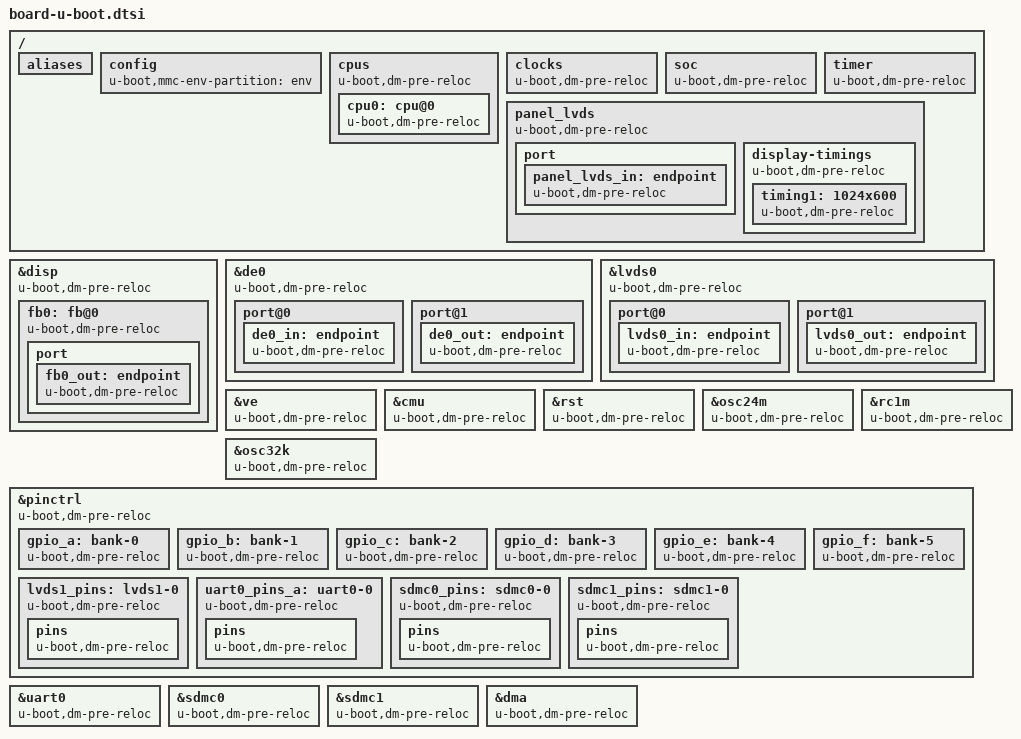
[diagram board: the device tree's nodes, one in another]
/ {
	aliases {
	};

	config {
		u-boot,mmc-env-partition = "env";
	};

	cpus {
		u-boot,dm-pre-reloc;
		cpu0: cpu@0 {
			u-boot,dm-pre-reloc;
		};
	};

	clocks {
		u-boot,dm-pre-reloc;
	};

	soc {
		u-boot,dm-pre-reloc;
	};

	timer {
		u-boot,dm-pre-reloc;
	};

	panel_lvds {
		u-boot,dm-pre-reloc;
		port {
			panel_lvds_in: endpoint {
				u-boot,dm-pre-reloc;
			};
		};

		display-timings {
			u-boot,dm-pre-reloc;
			timing1: 1024x600 {
				u-boot,dm-pre-reloc;
			};
		};
	};
};

&disp {
	u-boot,dm-pre-reloc;
	fb0: fb@0 {
	     u-boot,dm-pre-reloc;
		port {
			fb0_out: endpoint {
				u-boot,dm-pre-reloc;
			};
		};
	};
};
&de0 {
	u-boot,dm-pre-reloc;
	port@0 {
		de0_in: endpoint {
			u-boot,dm-pre-reloc;
		};
	};

	port@1 {
		de0_out: endpoint {
			u-boot,dm-pre-reloc;
		};
	};
};
&lvds0 {
	u-boot,dm-pre-reloc;
	port@0 {
		lvds0_in: endpoint {
			u-boot,dm-pre-reloc;
		};
	};

	port@1 {
		lvds0_out: endpoint {
			u-boot,dm-pre-reloc;
		};
	};
};
&ve {
	u-boot,dm-pre-reloc;
};

&cmu {
	u-boot,dm-pre-reloc;
};

&rst {
	u-boot,dm-pre-reloc;
};

&osc24m {
	u-boot,dm-pre-reloc;
};

&rc1m {
	u-boot,dm-pre-reloc;
};

&osc32k {
	u-boot,dm-pre-reloc;
};

&rst {
	u-boot,dm-pre-reloc;
};

&pinctrl {
	u-boot,dm-pre-reloc;
	gpio_a: bank-0 {
		u-boot,dm-pre-reloc;
	};
	gpio_b: bank-1 {
		u-boot,dm-pre-reloc;
	};
	gpio_c: bank-2 {
		u-boot,dm-pre-reloc;
	};
	gpio_d: bank-3 {
		u-boot,dm-pre-reloc;
	};
	gpio_e: bank-4 {
		u-boot,dm-pre-reloc;
	};
	gpio_f: bank-5 {
		u-boot,dm-pre-reloc;
	};
	lvds1_pins: lvds1-0 {
			u-boot,dm-pre-reloc;
		pins {
			u-boot,dm-pre-reloc;
		};
	};
	uart0_pins_a: uart0-0 {
		u-boot,dm-pre-reloc;
		pins {
			u-boot,dm-pre-reloc;
		};
	};
	sdmc0_pins: sdmc0-0 {
		u-boot,dm-pre-reloc;
		pins {
			u-boot,dm-pre-reloc;
		};
	};
	sdmc1_pins: sdmc1-0 {
		u-boot,dm-pre-reloc;
		pins {
			u-boot,dm-pre-reloc;
		};
	};
};

&uart0 {
	u-boot,dm-pre-reloc;
};

&sdmc0 {
	u-boot,dm-pre-reloc;
};

&sdmc1 {
	u-boot,dm-pre-reloc;
};

&dma {
	u-boot,dm-pre-reloc;
};
